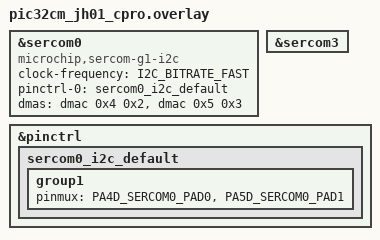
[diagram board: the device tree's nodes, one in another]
/*
 * Copyright (c) 2026 Microchip Technology Inc.
 *
 * SPDX-License-Identifier: Apache-2.0
 */

/* connect the PA22(EXT1 pin 11) to PA04(EXT2 pin 4) and PA23(EXT1 pin 12)  to PA05(EXT2 pin 3) */

dut: &sercom0 {
	compatible = "microchip,sercom-g1-i2c";
	#address-cells = <1>;
	#size-cells = <0>;
	clock-frequency = <I2C_BITRATE_FAST>;
	pinctrl-0 = <&sercom0_i2c_default>;
	pinctrl-names = "default";
	dmas = <&dmac 0x4 0x2>, <&dmac 0x5 0x3>;
	dma-names = "rx", "tx";
	status = "okay";
};

dut_aux: &sercom3 {
	status = "okay";
};

&pinctrl {
	sercom0_i2c_default: sercom0_i2c_default {
		group1 {
			pinmux = <PA4D_SERCOM0_PAD0>,
				 <PA5D_SERCOM0_PAD1>;
		};
	};
};
